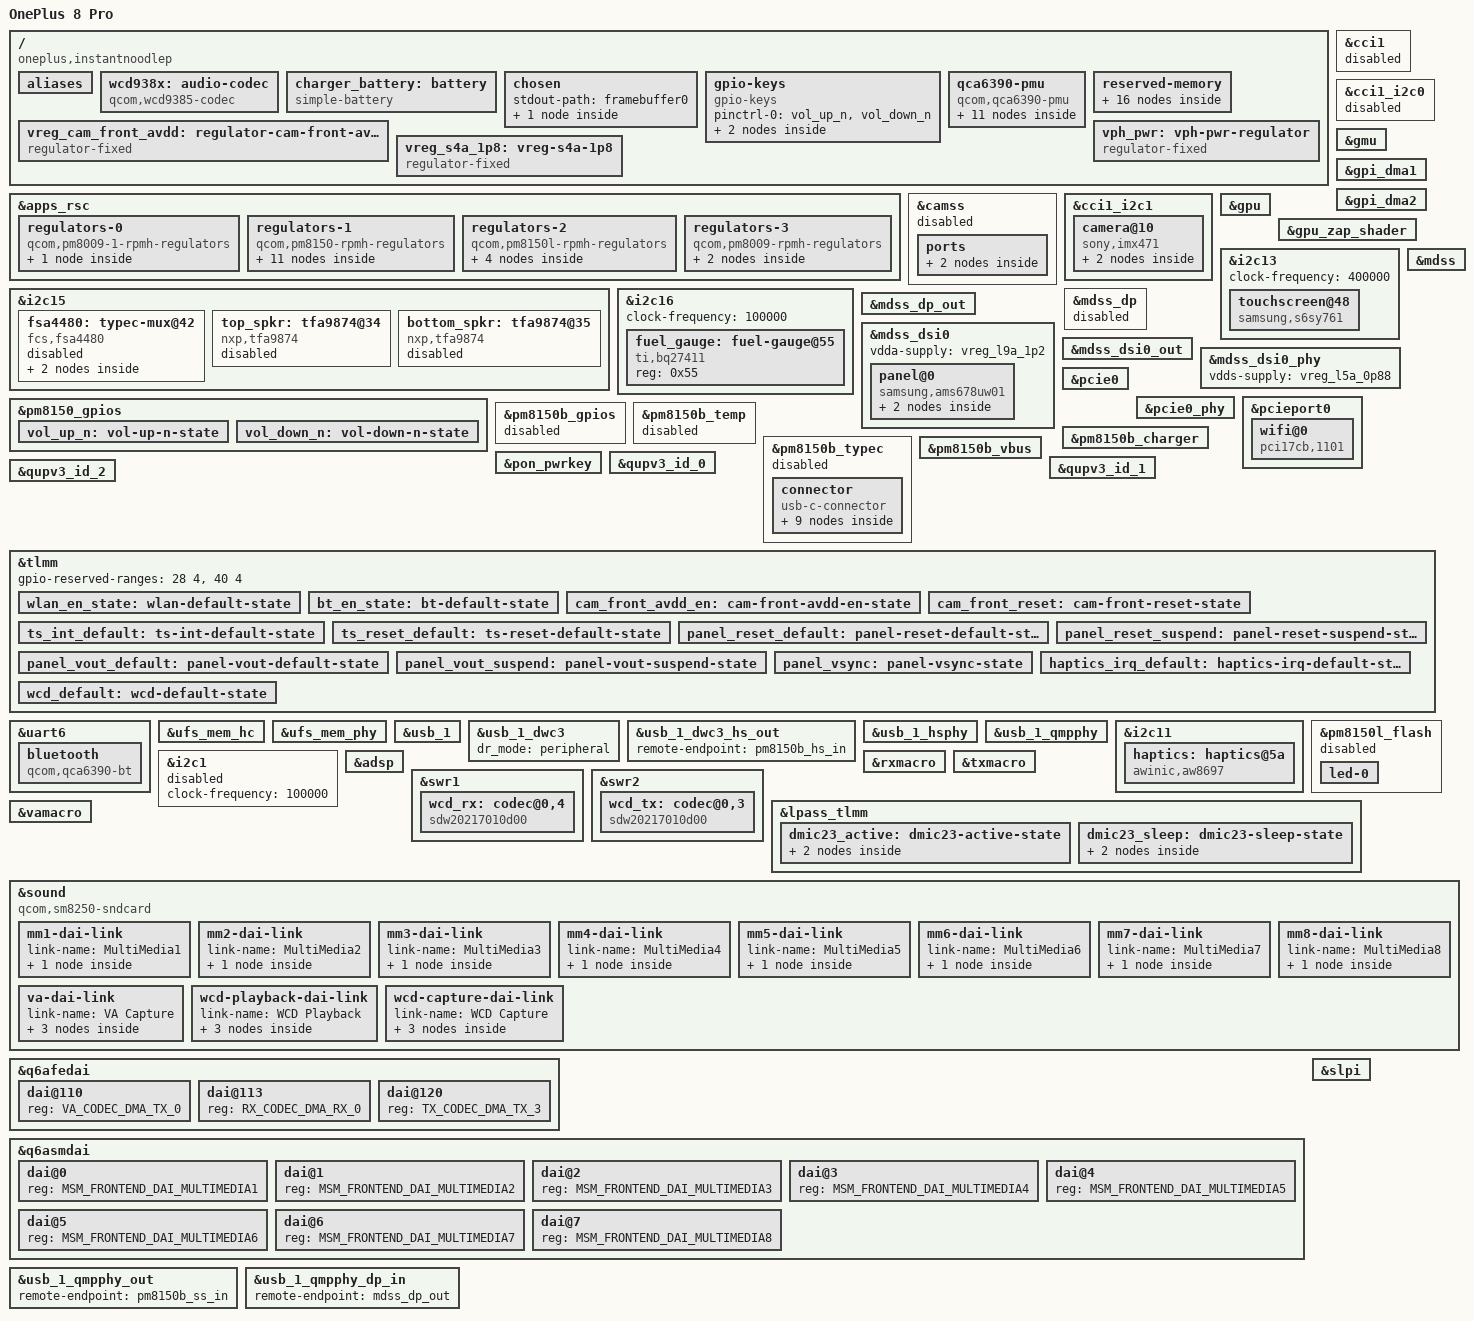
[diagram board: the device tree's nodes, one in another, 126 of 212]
// SPDX-License-Identifier: GPL-2.0
/*
 * Copyright (c) 2023 Pangwalla <pangwalla@protonmail.com>
 *
 * Minimal board support, carried over from the community
 * sm8250-oneplus-instantnoodlep.dts (qualcomm-sm8250 linux, tag 7.2.0-dev).
 */

/dts-v1/;

#include <dt-bindings/gpio/gpio.h>
#include <dt-bindings/input/input.h>
#include <dt-bindings/leds/common.h>
#include <dt-bindings/interrupt-controller/irq.h>
#include <dt-bindings/regulator/qcom,rpmh-regulator.h>
#include <dt-bindings/sound/qcom,q6asm.h>
#include <dt-bindings/sound/qcom,q6dsp-lpass-ports.h>
#include <dt-bindings/usb/pd.h>
#include "sm8250.dtsi"
#include "pm8150.dtsi"
#include "pm8150b.dtsi"
#include "pm8150l.dtsi"
#include "pm8009.dtsi"

/*
 * Delete following upstream (sm8250.dtsi) reserved
 * memory mappings which are different on this device.
 */
/delete-node/ &removed_mem;
/delete-node/ &camera_mem;
/delete-node/ &wlan_mem;
/delete-node/ &ipa_fw_mem;
/delete-node/ &ipa_gsi_mem;
/delete-node/ &gpu_mem;
/delete-node/ &npu_mem;
/delete-node/ &video_mem;
/delete-node/ &cvp_mem;
/delete-node/ &cdsp_mem;
/delete-node/ &slpi_mem;
/delete-node/ &adsp_mem;
/delete-node/ &spss_mem;
/delete-node/ &cdsp_secure_heap;

/ {
	model = "OnePlus 8 Pro";
	compatible = "oneplus,instantnoodlep", "qcom,sm8250";
	chassis-type = "handset";

	qcom,msm-id = <0x164 0x10000>, <0x164 0x20001>;
	qcom,board-id = <0x08 0x00>, <0x00 0x00>;

	aliases {
		serial1 = &uart6;
		i2c1 = &i2c1;
	};

	wcd938x: audio-codec {
		compatible = "qcom,wcd9385-codec";

		pinctrl-0 = <&wcd_default>;
		pinctrl-names = "default";

		qcom,mbhc-buttons-vthreshold-microvolt =
			<75000 150000 237000 500000 500000 500000 500000 500000>;
		qcom,mbhc-headset-vthreshold-microvolt = <2600000>;
		qcom,mbhc-headphone-vthreshold-microvolt = <75000>;
		qcom,micbias1-microvolt = <1800000>;
		qcom,micbias2-microvolt = <2700000>;
		qcom,micbias3-microvolt = <1800000>;
		qcom,micbias4-microvolt = <1800000>;
		qcom,rx-device = <&wcd_rx>;
		qcom,tx-device = <&wcd_tx>;

		reset-gpios = <&tlmm 32 GPIO_ACTIVE_LOW>;

		vdd-buck-supply = <&vreg_s4a_1p8>;
		vdd-rxtx-supply = <&vreg_s4a_1p8>;
		vdd-io-supply = <&vreg_s4a_1p8>;
		vdd-mic-bias-supply = <&vreg_bob>;

		#sound-dai-cells = <1>;
	};

	/*
	 * For the charger only: the fuel gauge must not reference this node,
	 * see &i2c16. 4.35 V is the rated cell voltage, used only without
	 * the fuel-gauge policy; 2 A is the stock normal-temperature limit.
	 */
	charger_battery: battery {
		compatible = "simple-battery";
		voltage-max-design-microvolt = <4350000>;
		constant-charge-current-max-microamp = <2000000>;
	};

	chosen {
		#address-cells = <2>;
		#size-cells = <2>;
		ranges;
		stdout-path = "framebuffer0";

		framebuffer0: framebuffer@9c000000 {
			compatible = "simple-framebuffer";
			reg = <0x0 0x9c000000 0x0 (1080 * 2376 * 4)>;
			width = <1080>;
			height = <2376>;
			stride = <(1080 * 4)>;
			format = "a8r8g8b8";
			clocks = <&dispcc DISP_CC_MDSS_AHB_CLK>,
				 <&gcc GCC_DISP_HF_AXI_CLK>,
				 <&gcc GCC_DISP_SF_AXI_CLK>,
				 <&dispcc DISP_CC_MDSS_VSYNC_CLK>,
				 <&dispcc DISP_CC_MDSS_MDP_CLK>,
				 <&dispcc DISP_CC_MDSS_BYTE0_CLK>,
				 <&dispcc DISP_CC_MDSS_BYTE0_INTF_CLK>,
				 <&dispcc DISP_CC_MDSS_PCLK0_CLK>,
				 <&dispcc DISP_CC_MDSS_ESC0_CLK>;
			power-domains = <&dispcc MDSS_GDSC>;
		};
	};

	gpio-keys {
		compatible = "gpio-keys";

		pinctrl-0 = <&vol_up_n>, <&vol_down_n>;
		pinctrl-names = "default";

		key-vol-up {
			label = "Volume Up";
			gpios = <&pm8150_gpios 6 GPIO_ACTIVE_LOW>;
			linux,code = <KEY_VOLUMEUP>;
			debounce-interval = <15>;
			linux,can-disable;
			wakeup-source;
		};

		key-vol-down {
			label = "Volume Down";
			gpios = <&pm8150_gpios 7 GPIO_ACTIVE_LOW>;
			linux,code = <KEY_VOLUMEDOWN>;
			debounce-interval = <15>;
			linux,can-disable;
			wakeup-source;
		};
	};

	qca6390-pmu {
		compatible = "qcom,qca6390-pmu";

		pinctrl-0 = <&bt_en_state>, <&wlan_en_state>;
		pinctrl-names = "default";

		vddaon-supply = <&vreg_s6a_0p95>;
		vddpmu-supply = <&vreg_s2f_0p95>;
		vddrfa0p95-supply = <&vreg_s2f_0p95>;
		vddrfa1p3-supply = <&vreg_s8c_1p3>;
		vddrfa1p9-supply = <&vreg_s5a_1p9>;
		vddpcie1p3-supply = <&vreg_s8c_1p3>;
		vddpcie1p9-supply = <&vreg_s5a_1p9>;
		vddio-supply = <&vreg_s4a_1p8>;

		wlan-enable-gpios = <&tlmm 20 GPIO_ACTIVE_HIGH>;
		bt-enable-gpios = <&tlmm 21 GPIO_ACTIVE_HIGH>;

		regulators {
			vreg_pmu_rfa_cmn: ldo0 {
				regulator-name = "vreg_pmu_rfa_cmn";
			};

			vreg_pmu_aon_0p59: ldo1 {
				regulator-name = "vreg_pmu_aon_0p59";
			};

			vreg_pmu_wlcx_0p8: ldo2 {
				regulator-name = "vreg_pmu_wlcx_0p8";
			};

			vreg_pmu_wlmx_0p85: ldo3 {
				regulator-name = "vreg_pmu_wlmx_0p85";
			};

			vreg_pmu_btcmx_0p85: ldo4 {
				regulator-name = "vreg_pmu_btcmx_0p85";
			};

			vreg_pmu_rfa_0p8: ldo5 {
				regulator-name = "vreg_pmu_rfa_0p8";
			};

			vreg_pmu_rfa_1p2: ldo6 {
				regulator-name = "vreg_pmu_rfa_1p2";
			};

			vreg_pmu_rfa_1p7: ldo7 {
				regulator-name = "vreg_pmu_rfa_1p7";
			};

			vreg_pmu_pcie_0p9: ldo8 {
				regulator-name = "vreg_pmu_pcie_0p9";
			};

			vreg_pmu_pcie_1p8: ldo9 {
				regulator-name = "vreg_pmu_pcie_1p8";
			};
		};
	};

	vreg_cam_front_avdd: regulator-cam-front-avdd {
		compatible = "regulator-fixed";
		regulator-name = "cam_front_avdd";
		regulator-min-microvolt = <2800000>;
		regulator-max-microvolt = <2800000>;
		startup-delay-us = <2000>;
		gpio = <&tlmm 24 GPIO_ACTIVE_HIGH>;
		enable-active-high;
		vin-supply = <&vreg_bob>;
		pinctrl-0 = <&cam_front_avdd_en>;
		pinctrl-names = "default";
	};

	reserved-memory {
		removed_mem: memory@80b00000 {
			reg = <0x0 0x80b00000 0x0 0xcd00000>;
			no-map;
		};

		camera_mem: memory@8dc00000 {
			reg = <0x0 0x8dc00000 0x0 0x500000>;
			no-map;
		};

		wlan_mem: memory@8e100000 {
			reg = <0x0 0x8e100000 0x0 0x100000>;
			no-map;
		};

		ipa_fw_mem: memory@8e200000 {
			reg = <0x0 0x8e200000 0x0 0x10000>;
			no-map;
		};

		ipa_gsi_mem: memory@8e210000 {
			reg = <0x0 0x8e210000 0x0 0xa000>;
			no-map;
		};

		gpu_mem: memory@8e21a000 {
			reg = <0x0 0x8e21a000 0x0 0x2000>;
			no-map;
		};

		npu_mem: memory@8e300000 {
			reg = <0x0 0x8e300000 0x0 0x500000>;
			no-map;
		};

		video_mem: memory@8e800000 {
			reg = <0x0 0x8e800000 0x0 0x500000>;
			no-map;
		};

		cvp_mem: memory@8ed00000 {
			reg = <0x0 0x8ed00000 0x0 0x500000>;
			no-map;
		};

		cdsp_mem: memory@8f200000 {
			reg = <0x0 0x8f200000 0x0 0x1400000>;
			no-map;
		};

		slpi_mem: memory@90600000 {
			reg = <0x0 0x90600000 0x0 0x1500000>;
			no-map;
		};

		adsp_mem: memory@91b00000 {
			reg = <0x0 0x91b00000 0x0 0x2500000>;
			no-map;
		};

		spss_mem: memory@94000000 {
			reg = <0x0 0x94000000 0x0 0x100000>;
			no-map;
		};

		cdsp_secure_heap: memory@94100000 {
			reg = <0x0 0x94100000 0x0 0x4600000>;
			no-map;
		};

		cont_splash_mem: memory@9c000000 {
			reg = <0x0 0x9c000000 0x0 0x2300000>;
			no-map;
		};

		ramoops@b0000000 {
			compatible = "ramoops";
			reg = <0x0 0xb0000000 0x0 0x400000>;
			record-size = <0x40000>;
			console-size = <0x40000>;
			pmsg-size = <0x40000>;
			ecc-size = <0x0>;
			no-map;
		};
	};

	vph_pwr: vph-pwr-regulator {
		compatible = "regulator-fixed";
		regulator-name = "vph_pwr";
		regulator-min-microvolt = <3700000>;
		regulator-max-microvolt = <3700000>;
	};

	vreg_s4a_1p8: vreg-s4a-1p8 {
		compatible = "regulator-fixed";
		regulator-name = "vreg_s4a_1p8";
		regulator-min-microvolt = <1800000>;
		regulator-max-microvolt = <1800000>;
		regulator-always-on;
	};
};

&apps_rsc {
	regulators-0 {
		compatible = "qcom,pm8009-1-rpmh-regulators";
		qcom,pmic-id = "f";

		vdd-s1-supply = <&vph_pwr>;
		vdd-s2-supply = <&vph_pwr>;

		vreg_s2f_0p95: smps2 {
			regulator-name = "vreg_s2f_0p95";
			regulator-min-microvolt = <900000>;
			regulator-max-microvolt = <952000>;
			regulator-initial-mode = <RPMH_REGULATOR_MODE_AUTO>;
		};
	};

	regulators-1 {
		compatible = "qcom,pm8150-rpmh-regulators";
		qcom,pmic-id = "a";

		vdd-s1-supply = <&vph_pwr>;
		vdd-s2-supply = <&vph_pwr>;
		vdd-s3-supply = <&vph_pwr>;
		vdd-s4-supply = <&vph_pwr>;
		vdd-s5-supply = <&vph_pwr>;
		vdd-s6-supply = <&vph_pwr>;
		vdd-s7-supply = <&vph_pwr>;
		vdd-s8-supply = <&vph_pwr>;
		vdd-s9-supply = <&vph_pwr>;
		vdd-s10-supply = <&vph_pwr>;
		vdd-l2-l10-supply = <&vreg_bob>;
		vdd-l3-l4-l5-l18-supply = <&vreg_s6a_0p95>;
		vdd-l6-l9-supply = <&vreg_s8c_1p3>;
		vdd-l7-l12-l14-l15-supply = <&vreg_s5a_1p9>;
		vdd-l13-l16-l17-supply = <&vreg_bob>;

		vreg_l2a_3p1: ldo2 {
			regulator-name = "vreg_l2a_3p1";
			regulator-min-microvolt = <3072000>;
			regulator-max-microvolt = <3072000>;
			regulator-initial-mode = <RPMH_REGULATOR_MODE_HPM>;
		};

		vreg_l5a_0p88: ldo5 {
			regulator-name = "vreg_l5a_0p88";
			regulator-min-microvolt = <880000>;
			regulator-max-microvolt = <880000>;
			regulator-initial-mode = <RPMH_REGULATOR_MODE_HPM>;
		};

		vreg_l6a_1p2: ldo6 {
			regulator-name = "vreg_l6a_1p2";
			regulator-min-microvolt = <1200000>;
			regulator-max-microvolt = <1200000>;
			regulator-initial-mode = <RPMH_REGULATOR_MODE_HPM>;
		};

		vreg_l9a_1p2: ldo9 {
			regulator-name = "vreg_l9a_1p2";
			regulator-min-microvolt = <1200000>;
			regulator-max-microvolt = <1200000>;
			regulator-initial-mode = <RPMH_REGULATOR_MODE_HPM>;
		};

		vreg_l12a_1p8: ldo12 {
			regulator-name = "vreg_l12a_1p8";
			regulator-min-microvolt = <1800000>;
			regulator-max-microvolt = <1800000>;
			regulator-initial-mode = <RPMH_REGULATOR_MODE_HPM>;
		};

		vreg_l13a_ts_3p0: ldo13 {
			regulator-name = "vreg_l13a_ts_3p0";
			regulator-min-microvolt = <3008000>;
			regulator-max-microvolt = <3008000>;
			regulator-initial-mode = <RPMH_REGULATOR_MODE_HPM>;
		};

		vreg_l14a_1p8: ldo14 {
			regulator-name = "vreg_l14a_1p8";
			regulator-min-microvolt = <1800000>;
			regulator-max-microvolt = <1880000>;
			regulator-initial-mode = <RPMH_REGULATOR_MODE_HPM>;
		};

		vreg_l17a_3p0: ldo17 {
			regulator-name = "vreg_l17a_3p0";
			regulator-min-microvolt = <2856000>;
			regulator-max-microvolt = <3008000>;
			regulator-initial-mode = <RPMH_REGULATOR_MODE_HPM>;
		};

		vreg_l18a_0p92: ldo18 {
			regulator-name = "vreg_l18a_0p92";
			regulator-min-microvolt = <800000>;
			regulator-max-microvolt = <912000>;
			regulator-initial-mode = <RPMH_REGULATOR_MODE_HPM>;
		};

		vreg_s5a_1p9: smps5 {
			regulator-name = "vreg_s5a_1p9";
			regulator-min-microvolt = <1904000>;
			regulator-max-microvolt = <2000000>;
			regulator-initial-mode = <RPMH_REGULATOR_MODE_HPM>;
		};

		vreg_s6a_0p95: smps6 {
			regulator-name = "vreg_s6a_0p95";
			regulator-min-microvolt = <920000>;
			regulator-max-microvolt = <1128000>;
			regulator-initial-mode = <RPMH_REGULATOR_MODE_HPM>;
		};
	};

	regulators-2 {
		compatible = "qcom,pm8150l-rpmh-regulators";
		qcom,pmic-id = "c";

		vdd-s1-supply = <&vph_pwr>;
		vdd-s2-supply = <&vph_pwr>;
		vdd-s3-supply = <&vph_pwr>;
		vdd-s4-supply = <&vph_pwr>;
		vdd-s5-supply = <&vph_pwr>;
		vdd-s6-supply = <&vph_pwr>;
		vdd-s7-supply = <&vph_pwr>;
		vdd-s8-supply = <&vph_pwr>;
		vdd-l1-l8-supply = <&vreg_s4a_1p8>;
		vdd-l2-l3-supply = <&vreg_s8c_1p3>;
		vdd-l4-l5-l6-supply = <&vreg_bob>;
		vdd-l7-l11-supply = <&vreg_bob>;
		vdd-l9-l10-supply = <&vreg_bob>;
		vdd-bob-supply = <&vph_pwr>;

		vreg_bob: bob {
			regulator-name = "vreg_bob";
			regulator-min-microvolt = <3008000>;
			regulator-max-microvolt = <4000000>;
			regulator-initial-mode = <RPMH_REGULATOR_MODE_AUTO>;
		};

		vreg_l1c_1p8: ldo1 {
			regulator-name = "vreg_l1c_1p8";
			regulator-min-microvolt = <1800000>;
			regulator-max-microvolt = <1800000>;
			regulator-initial-mode = <RPMH_REGULATOR_MODE_HPM>;
		};

		vreg_l11c_3p3: ldo11 {
			regulator-name = "vreg_l11c_3p3";
			regulator-min-microvolt = <3296000>;
			regulator-max-microvolt = <3296000>;
			regulator-initial-mode = <RPMH_REGULATOR_MODE_HPM>;
			regulator-always-on;
		};

		vreg_s8c_1p3: smps8 {
			regulator-name = "vreg_s8c_1p3";
			regulator-min-microvolt = <1352000>;
			regulator-max-microvolt = <1352000>;
			regulator-initial-mode = <RPMH_REGULATOR_MODE_HPM>;
		};
	};
	regulators-3 {
		compatible = "qcom,pm8009-rpmh-regulators";
		qcom,pmic-id = "f";
		vdd-l7-supply = <&vreg_s4a_1p8>;

		vreg_l3f_1p05: ldo3 {
			regulator-name = "vreg_l3f_1p05";
			regulator-min-microvolt = <1056000>;
			regulator-max-microvolt = <1056000>;
			regulator-initial-mode = <RPMH_REGULATOR_MODE_HPM>;
		};

		vreg_l7f_1p8: ldo7 {
			regulator-name = "vreg_l7f_1p8";
			regulator-min-microvolt = <1800000>;
			regulator-max-microvolt = <1800000>;
			regulator-initial-mode = <RPMH_REGULATOR_MODE_HPM>;
		};
	};

};


/* Front camera: the 2026-11-18 RAM boot of slim-cam hung before root; off until fixed. */
&camss {
	vdda-phy-supply = <&vreg_l5a_0p88>;
	vdda-pll-supply = <&vreg_l9a_1p2>;
	status = "disabled";

	ports {
		port@3 {
			csiphy3_ep: endpoint {
				clock-lanes = <7>;
				data-lanes = <0 1 2 3>;
				remote-endpoint = <&cam_front_ep>;
			};
		};
	};
};

&cci1 {
	pinctrl-0 = <&cci1_i2c1_default>;
	pinctrl-1 = <&cci1_i2c1_sleep>;
	status = "disabled";
};

&cci1_i2c0 {
	status = "disabled";
};

&cci1_i2c1 {
	camera@10 {
		compatible = "sony,imx471";
		reg = <0x10>;
		clocks = <&camcc CAM_CC_MCLK3_CLK>;
		assigned-clocks = <&camcc CAM_CC_MCLK3_CLK>;
		assigned-clock-rates = <19200000>;
		reset-gpios = <&tlmm 78 GPIO_ACTIVE_LOW>;
		avdd-supply = <&vreg_cam_front_avdd>;
		dvdd-supply = <&vreg_l3f_1p05>;
		dovdd-supply = <&vreg_l7f_1p8>;
		pinctrl-0 = <&cam_mclk3_default>, <&cam_front_reset>;
		pinctrl-names = "default";
		orientation = <0>;
		rotation = <90>;

		port {
			cam_front_ep: endpoint {
				data-lanes = <1 2 3 4>;
				link-frequencies = /bits/ 64 <200000000>;
				remote-endpoint = <&csiphy3_ep>;
			};
		};
	};
};

&gmu {
	status = "okay";
};

&gpi_dma1 {
	status = "okay";
};

&gpi_dma2 {
	status = "okay";
};

&gpu {
	status = "okay";
};

&gpu_zap_shader {
	firmware-name = "qcom/sm8250/OnePlus/instantnoodlep/a650_zap.mbn";
};

&i2c13 {
	clock-frequency = <400000>;
	status = "okay";

	touchscreen@48 {
		compatible = "samsung,s6sy761";
		reg = <0x48>;

		interrupts-extended = <&tlmm 39 IRQ_TYPE_LEVEL_LOW>;
		reset-gpios = <&tlmm 38 GPIO_ACTIVE_LOW>;

		vdd-supply = <&vreg_l13a_ts_3p0>;
		avdd-supply = <&vreg_l1c_1p8>;

		touchscreen-size-x = <1440>;
		touchscreen-size-y = <3168>;

		pinctrl-0 = <&ts_int_default>, <&ts_reset_default>;
		pinctrl-names = "default";
	};
};

&i2c15 {
	status = "okay";

	fsa4480: typec-mux@42 {
		compatible = "fcs,fsa4480";
		reg = <0x42>;
		status = "disabled";

		mode-switch;
		orientation-switch;

		port {
			fsa4480_sbu: endpoint {
				remote-endpoint = <&pm8150b_sbu>;
			};
		};
	};
};

&i2c16 {
	clock-frequency = <100000>;
	status = "okay";

	/*
	 * No monitored-battery: the bq27411 keeps its data memory in RAM,
	 * so the driver would rewrite the gauge's design capacity from a
	 * simple-battery node on every probe. The gauge stays as the stock
	 * firmware left it.
	 */
	fuel_gauge: fuel-gauge@55 {
		compatible = "ti,bq27411";
		reg = <0x55>;
	};
};

&mdss {
	status = "okay";
};

&mdss_dp {
	status = "disabled";
};

&mdss_dp_out {
	data-lanes = <0 1 2 3>;
	link-frequencies = /bits/ 64 <1620000000 2700000000 5400000000 8100000000>;
	remote-endpoint = <&usb_1_qmpphy_dp_in>;
};

&mdss_dsi0 {
	vdda-supply = <&vreg_l9a_1p2>;

	status = "okay";

	panel@0 {
		compatible = "samsung,ams678uw01";
		reg = <0>;

		reset-gpios = <&tlmm 75 GPIO_ACTIVE_LOW>;
		vddio-supply = <&vreg_l14a_1p8>;
		vdd-supply = <&vreg_l11c_3p3>;

		pinctrl-0 = <&panel_reset_default &panel_vout_default &panel_vsync>;
		pinctrl-1 = <&panel_reset_suspend &panel_vout_suspend &panel_vsync>;
		pinctrl-names = "default", "sleep";

		port {
			panel_in: endpoint {
				remote-endpoint = <&mdss_dsi0_out>;
			};
		};
	};
};

&mdss_dsi0_out {
	data-lanes = <0 1 2 3>;
	remote-endpoint = <&panel_in>;
};

&mdss_dsi0_phy {
	vdds-supply = <&vreg_l5a_0p88>;

	status = "okay";
};

&pcie0 {
	status = "okay";
};

&pcie0_phy {
	vdda-phy-supply = <&vreg_l5a_0p88>;
	vdda-pll-supply = <&vreg_l9a_1p2>;

	status = "okay";
};

&pcieport0 {
	wifi@0 {
		compatible = "pci17cb,1101";
		reg = <0x10000 0x0 0x0 0x0 0x0>;

		vddrfacmn-supply = <&vreg_pmu_rfa_cmn>;
		vddaon-supply = <&vreg_pmu_aon_0p59>;
		vddwlcx-supply = <&vreg_pmu_wlcx_0p8>;
		vddwlmx-supply = <&vreg_pmu_wlmx_0p85>;
		vddrfa0p8-supply = <&vreg_pmu_rfa_0p8>;
		vddrfa1p2-supply = <&vreg_pmu_rfa_1p2>;
		vddrfa1p7-supply = <&vreg_pmu_rfa_1p7>;
		vddpcie0p9-supply = <&vreg_pmu_pcie_0p9>;
		vddpcie1p8-supply = <&vreg_pmu_pcie_1p8>;
	};
};

&pm8150_gpios {
	vol_up_n: vol-up-n-state {
		pins = "gpio6";
		function = "normal";
		power-source = <1>;
		input-enable;
		bias-pull-up;
	};

	vol_down_n: vol-down-n-state {
		pins = "gpio7";
		function = "normal";
		power-source = <1>;
		input-enable;
		bias-pull-up;
	};
};

/* Test-only: nothing uses these; keep them out of the charger test. */
&pm8150b_gpios {
	status = "disabled";
};

&pm8150b_temp {
	status = "disabled";
};

&pm8150b_charger {
	monitored-battery = <&charger_battery>;
	/* The gauge at the cell decides when the battery is full, as in stock. */
	qcom,fuel-gauge = <&fuel_gauge>;
	status = "okay";
};

&pm8150b_typec {
	status = "disabled";

	vdd-pdphy-supply = <&vreg_l2a_3p1>;
	vdd-vbus-supply = <&pm8150b_vbus>;

	connector {
		compatible = "usb-c-connector";

		power-role = "dual";
		data-role = "dual";
		self-powered;

		/*
		 * 5 V only until the charger is qualified: stock also offers
		 * 9 V/3 A and 12 V/2.25 A (stock dtbo entry 16), but no driver
		 * programs the PM8150B charger on this kernel.
		 */
		sink-pdos = <PDO_FIXED(5000, 3000, PDO_FIXED_USB_COMM)>;
		op-sink-microwatt = <10000000>;
		source-pdos = <PDO_FIXED(5000, 3000,
					 PDO_FIXED_DUAL_ROLE |
					 PDO_FIXED_USB_COMM |
					 PDO_FIXED_DATA_SWAP)>;

		altmodes {
			displayport {
				svid = /bits/ 16 <0xff01>;
				vdo = <0x00001c46>;
			};
		};

		ports {
			#address-cells = <1>;
			#size-cells = <0>;

			port@0 {
				reg = <0>;
				pm8150b_hs_in: endpoint {
					remote-endpoint = <&usb_1_dwc3_hs_out>;
				};
			};

			port@1 {
				reg = <1>;
				pm8150b_ss_in: endpoint {
					remote-endpoint = <&usb_1_qmpphy_out>;
				};
			};

			port@2 {
				reg = <2>;
				pm8150b_sbu: endpoint {
					remote-endpoint = <&fsa4480_sbu>;
				};
			};
		};
	};
};

&pm8150b_vbus {
	regulator-min-microamp = <500000>;
	regulator-max-microamp = <3000000>;
	status = "okay";
};

&pon_pwrkey {
	status = "okay";
};

&qupv3_id_0 {
	status = "okay";
};

&qupv3_id_1 {
	status = "okay";
};

&qupv3_id_2 {
	status = "okay";
};

&tlmm {
	gpio-reserved-ranges = <28 4>, <40 4>;

	wlan_en_state: wlan-default-state {
		pins = "gpio20";
		function = "gpio";
		drive-strength = <16>;
		output-low;
		bias-pull-up;
	};

	bt_en_state: bt-default-state {
		pins = "gpio21";
		function = "gpio";
		drive-strength = <16>;
		output-low;
		bias-pull-up;
	};

	cam_front_avdd_en: cam-front-avdd-en-state {
		pins = "gpio24";
		function = "gpio";
		drive-strength = <2>;
		bias-disable;
	};

	cam_front_reset: cam-front-reset-state {
		pins = "gpio78";
		function = "gpio";
		drive-strength = <2>;
		bias-disable;
	};

	ts_int_default: ts-int-default-state {
		pins = "gpio39";
		function = "gpio";
		drive-strength = <2>;
		bias-pull-up;
	};

	ts_reset_default: ts-reset-default-state {
		pins = "gpio38";
		function = "gpio";
		drive-strength = <2>;
		bias-disable;
	};

	panel_reset_default: panel-reset-default-state {
		pins = "gpio75";
		function = "gpio";
		drive-strength = <8>;
		bias-disable;
	};

	panel_reset_suspend: panel-reset-suspend-state {
		pins = "gpio75";
		function = "gpio";
		drive-strength = <2>;
		bias-pull-down;
	};

	panel_vout_default: panel-vout-default-state {
		pins = "gpio8";
		function = "gpio";
		drive-strength = <8>;
		bias-disable;
		output-high;
	};

	panel_vout_suspend: panel-vout-suspend-state {
		pins = "gpio8";
		function = "gpio";
		drive-strength = <2>;
		bias-pull-down;
		output-low;
	};

	panel_vsync: panel-vsync-state {
		pins = "gpio66";
		function = "mdp_vsync";
		drive-strength = <2>;
		bias-pull-down;
	};
};

&uart6 {
	status = "okay";

	bluetooth {
		compatible = "qcom,qca6390-bt";

		vddrfacmn-supply = <&vreg_pmu_rfa_cmn>;
		vddaon-supply = <&vreg_pmu_aon_0p59>;
		vddbtcmx-supply = <&vreg_pmu_btcmx_0p85>;
		vddrfa0p8-supply = <&vreg_pmu_rfa_0p8>;
		vddrfa1p2-supply = <&vreg_pmu_rfa_1p2>;
		vddrfa1p7-supply = <&vreg_pmu_rfa_1p7>;
	};
};

&ufs_mem_hc {
	vcc-supply = <&vreg_l17a_3p0>;
	vcc-max-microamp = <800000>;
	vccq-supply = <&vreg_l6a_1p2>;
	vccq-max-microamp = <800000>;
	vccq2-supply = <&vreg_s4a_1p8>;
	vccq2-max-microamp = <800000>;
	status = "okay";
};

&ufs_mem_phy {
	vdda-phy-supply = <&vreg_l5a_0p88>;
	vdda-pll-supply = <&vreg_l9a_1p2>;
	status = "okay";
};

&usb_1 {
	/*
	 * TEST ONLY, not for merging: hold clocks that nobody claims, to find
	 * which one USB needs when clk_ignore_unused is dropped. dwc3-qcom
	 * enables every clock listed here.
	 */
	clocks = <&gcc GCC_CFG_NOC_USB3_PRIM_AXI_CLK>,
		 <&gcc GCC_USB30_PRIM_MASTER_CLK>,
		 <&gcc GCC_AGGRE_USB3_PRIM_AXI_CLK>,
		 <&gcc GCC_USB30_PRIM_SLEEP_CLK>,
		 <&gcc GCC_USB30_PRIM_MOCK_UTMI_CLK>,
		 <&gcc GCC_USB3_SEC_CLKREF_EN>,
		 <&gcc GCC_QUPV3_WRAP1_CORE_CLK>,
		 <&gcc GCC_QUPV3_WRAP1_CORE_2X_CLK>;
	clock-names = "cfg_noc",
		      "core",
		      "iface",
		      "sleep",
		      "mock_utmi",
		      "xo",
		      "test_w1core",
		      "test_w1core2x";
	status = "okay";
};

&usb_1_dwc3 {
	/* Keep the tested USB gadget path independent of the Type-C stack. */
	dr_mode = "peripheral";
};

&usb_1_dwc3_hs_out {
	remote-endpoint = <&pm8150b_hs_in>;
};

&usb_1_hsphy {
	vdda-pll-supply = <&vreg_l5a_0p88>;
	vdda18-supply = <&vreg_l12a_1p8>;
	vdda33-supply = <&vreg_l2a_3p1>;
	status = "okay";
};

&usb_1_qmpphy {
	vdda-phy-supply = <&vreg_l9a_1p2>;
	vdda-pll-supply = <&vreg_l18a_0p92>;
	status = "okay";
};

/* Haptics passed the bounded M3a test on 2026-11-18 (RAM boot). */
&i2c11 {
	status = "okay";

	haptics: haptics@5a {
		compatible = "awinic,aw8697";
		reg = <0x5a>;
		interrupts-extended = <&tlmm 118 IRQ_TYPE_EDGE_FALLING>;
		reset-gpios = <&tlmm 72 GPIO_ACTIVE_HIGH>;
		pinctrl-names = "default";
		pinctrl-0 = <&haptics_irq_default>;
		awinic,f0-preset = <1700>;
		awinic,f0-coefficient = <260>;
		awinic,f0-calibration-percent = <7>;
		awinic,drive-level = <54>;
		awinic,f0-detection-play-time = <5>;
		awinic,f0-detection-wait-time = <3>;
		awinic,f0-detection-repeat = <2>;
		awinic,f0-detection-trace = <15>;
		awinic,boost-debug = /bits/ 8 <0x30 0xeb 0xd4>;
		awinic,tset = /bits/ 8 <0x12>;
		awinic,r-spare = /bits/ 8 <0x68>;
		awinic,bemf-upper-threshold = <4104>;
		awinic,bemf-lower-threshold = <1016>;
		status = "okay";
	};
};

&tlmm {
	haptics_irq_default: haptics-irq-default-state {
		pins = "gpio118";
		function = "gpio";
		drive-strength = <2>;
		bias-pull-up;
	};
};

/* No default trigger; never enable alongside the haptics first-test node. */
&pm8150l_flash {
	status = "disabled";

	led-0 {
		function = LED_FUNCTION_FLASH;
		color = <LED_COLOR_ID_WHITE>;
		led-sources = <1 2>;
		led-max-microamp = <20000>;
		flash-max-microamp = <25000>;
		flash-max-timeout-us = <10000>;
	};
};

/* Controller-only identification: never instantiate unverified Hall clients. */
&i2c1 {
	clock-frequency = <100000>;
	status = "disabled";
};

&adsp {
	status = "okay";
	firmware-name = "qcom/sm8250/OnePlus/instantnoodlep/adsp.mbn";
};

&rxmacro {
	status = "okay";
};

&txmacro {
	status = "okay";
};

&swr1 {
	status = "okay";

	wcd_rx: codec@0,4 {
		compatible = "sdw20217010d00";
		reg = <0 4>;
		qcom,rx-port-mapping = <1 2 3 4 5>;
	};
};

&swr2 {
	status = "okay";

	wcd_tx: codec@0,3 {
		compatible = "sdw20217010d00";
		reg = <0 3>;
		qcom,tx-port-mapping = <2 2 3 4>;
	};
};

&tlmm {
	wcd_default: wcd-default-state {
		pins = "gpio32";
		function = "gpio";
		drive-strength = <16>;
		output-low;
	};
};

/* TFA9874 support is staged separately; no speaker path in phase 1. */
&i2c15 {
	top_spkr: tfa9874@34 {
		compatible = "nxp,tfa9874";
		status = "disabled";
		reg = <0x34>;
		reset-gpios = <&tlmm 91 GPIO_ACTIVE_HIGH>;
		vddd-supply = <&vreg_s4a_1p8>;
		sound-channel = <0>;
		sound-name-prefix = "Top Speaker";
		#sound-dai-cells = <0>;
	};

	bottom_spkr: tfa9874@35 {
		compatible = "nxp,tfa9874";
		status = "disabled";
		reg = <0x35>;
		reset-gpios = <&tlmm 99 GPIO_ACTIVE_HIGH>;
		vddd-supply = <&vreg_s4a_1p8>;
		sound-channel = <1>;
		sound-name-prefix = "Bottom Speaker";
		#sound-dai-cells = <0>;
	};
};

&lpass_tlmm {
	dmic23_active: dmic23-active-state {
		clk-pins {
			pins = "gpio8";
			function = "dmic2_clk";
			drive-strength = <8>;
			output-high;
		};

		data-pins {
			pins = "gpio9";
			function = "dmic2_data";
			drive-strength = <8>;
			input-enable;
		};
	};

	dmic23_sleep: dmic23-sleep-state {
		clk-pins {
			pins = "gpio8";
			function = "dmic2_clk";
			drive-strength = <2>;
			bias-disable;
			output-low;
		};

		data-pins {
			pins = "gpio9";
			function = "dmic2_data";
			drive-strength = <2>;
			bias-pull-down;
			input-enable;
		};
	};
};

&vamacro {
	pinctrl-0 = <&dmic01_active>, <&dmic23_active>;
	pinctrl-1 = <&dmic01_sleep>, <&dmic23_sleep>;
	pinctrl-names = "default", "sleep";
	vdd-micb-supply = <&vreg_bob>;
	qcom,dmic-sample-rate = <2400000>;
};

&sound {
	compatible = "qcom,sm8250-sndcard";
	model = "OnePlus 8 Pro";
	audio-routing =
		"AMIC2", "MIC BIAS2",
		"TX DMIC0", "MIC BIAS1",
		"TX DMIC1", "MIC BIAS1",
		"TX DMIC2", "MIC BIAS3",
		"TX DMIC3", "MIC BIAS4",
		"TX DMIC4", "MIC BIAS4",
		"TX DMIC5", "MIC BIAS4",
		"DMIC1", "MIC BIAS1",
		"DMIC2", "MIC BIAS1",
		"DMIC3", "MIC BIAS3",
		"DMIC4", "MIC BIAS3",
		"DMIC5", "MIC BIAS4",
		"DMIC6", "MIC BIAS4",
		"IN1_HPHL", "HPHL_OUT",
		"IN2_HPHR", "HPHR_OUT",
		"IN3_AUX", "AUX_OUT",
		"TX SWR_ADC0", "ADC1_OUTPUT",
		"TX SWR_ADC1", "ADC2_OUTPUT",
		"TX SWR_ADC2", "ADC3_OUTPUT",
		"TX SWR_ADC3", "ADC4_OUTPUT",
		"TX SWR_DMIC0", "DMIC1_OUTPUT",
		"TX SWR_DMIC1", "DMIC2_OUTPUT",
		"TX SWR_DMIC2", "DMIC3_OUTPUT",
		"TX SWR_DMIC3", "DMIC4_OUTPUT",
		"TX SWR_DMIC4", "DMIC5_OUTPUT",
		"TX SWR_DMIC5", "DMIC6_OUTPUT",
		"TX SWR_DMIC6", "DMIC7_OUTPUT",
		"TX SWR_DMIC7", "DMIC8_OUTPUT",
		"RX_TX DEC0_INP", "TX DEC0 MUX",
		"RX_TX DEC1_INP", "TX DEC1 MUX",
		"RX_TX DEC2_INP", "TX DEC2 MUX",
		"RX_TX DEC3_INP", "TX DEC3 MUX",
		"VA DMIC0", "VA MIC BIAS1",
		"VA DMIC1", "VA MIC BIAS1",
		"VA DMIC2", "VA MIC BIAS3",
		"VA DMIC3", "VA MIC BIAS4",
		"VA DMIC4", "VA MIC BIAS4",
		"VA DMIC5", "VA MIC BIAS4",
		"VA SWR_ADC0", "ADC1_OUTPUT",
		"VA SWR_ADC1", "ADC2_OUTPUT",
		"VA SWR_ADC2", "ADC3_OUTPUT",
		"VA SWR_ADC3", "ADC4_OUTPUT",
		"VA SWR_MIC0", "DMIC1_OUTPUT",
		"VA SWR_MIC1", "DMIC2_OUTPUT",
		"VA SWR_MIC2", "DMIC3_OUTPUT",
		"VA SWR_MIC3", "DMIC4_OUTPUT",
		"VA SWR_MIC4", "DMIC5_OUTPUT",
		"VA SWR_MIC5", "DMIC6_OUTPUT",
		"VA SWR_MIC6", "DMIC7_OUTPUT",
		"VA SWR_MIC7", "DMIC8_OUTPUT";
	mm1-dai-link {
		link-name = "MultiMedia1";

		cpu {
			sound-dai = <&q6asmdai MSM_FRONTEND_DAI_MULTIMEDIA1>;
		};
	};

	mm2-dai-link {
		link-name = "MultiMedia2";

		cpu {
			sound-dai = <&q6asmdai MSM_FRONTEND_DAI_MULTIMEDIA2>;
		};
	};

	mm3-dai-link {
		link-name = "MultiMedia3";

		cpu {
			sound-dai = <&q6asmdai MSM_FRONTEND_DAI_MULTIMEDIA3>;
		};
	};

	mm4-dai-link {
		link-name = "MultiMedia4";

		cpu {
			sound-dai = <&q6asmdai MSM_FRONTEND_DAI_MULTIMEDIA4>;
		};
	};

	mm5-dai-link {
		link-name = "MultiMedia5";

		cpu {
			sound-dai = <&q6asmdai MSM_FRONTEND_DAI_MULTIMEDIA5>;
		};
	};

	mm6-dai-link {
		link-name = "MultiMedia6";

		cpu {
			sound-dai = <&q6asmdai MSM_FRONTEND_DAI_MULTIMEDIA6>;
		};
	};

	mm7-dai-link {
		link-name = "MultiMedia7";

		cpu {
			sound-dai = <&q6asmdai MSM_FRONTEND_DAI_MULTIMEDIA7>;
		};
	};

	mm8-dai-link {
		link-name = "MultiMedia8";

		cpu {
			sound-dai = <&q6asmdai MSM_FRONTEND_DAI_MULTIMEDIA8>;
		};
	};

	va-dai-link {
		link-name = "VA Capture";

		codec {
			sound-dai = <&vamacro 0>;
		};

		cpu {
			sound-dai = <&q6afedai VA_CODEC_DMA_TX_0>;
		};

		platform {
			sound-dai = <&q6routing>;
		};
	};

	wcd-playback-dai-link {
		link-name = "WCD Playback";

		codec {
			sound-dai = <&wcd938x 0>, <&swr1 0>, <&rxmacro 0>;
		};

		cpu {
			sound-dai = <&q6afedai RX_CODEC_DMA_RX_0>;
		};

		platform {
			sound-dai = <&q6routing>;
		};
	};

	wcd-capture-dai-link {
		link-name = "WCD Capture";

		codec {
			sound-dai = <&wcd938x 1>, <&swr2 0>, <&txmacro 0>;
		};

		cpu {
			sound-dai = <&q6afedai TX_CODEC_DMA_TX_3>;
		};

		platform {
			sound-dai = <&q6routing>;
		};
	};
};

&q6afedai {

	dai@110 {
		reg = <VA_CODEC_DMA_TX_0>;
	};

	dai@113 {
		reg = <RX_CODEC_DMA_RX_0>;
	};

	dai@120 {
		reg = <TX_CODEC_DMA_TX_3>;
	};

};

&q6asmdai {
	dai@0 {
		reg = <MSM_FRONTEND_DAI_MULTIMEDIA1>;
	};

	dai@1 {
		reg = <MSM_FRONTEND_DAI_MULTIMEDIA2>;
	};

	dai@2 {
		reg = <MSM_FRONTEND_DAI_MULTIMEDIA3>;
	};

	dai@3 {
		reg = <MSM_FRONTEND_DAI_MULTIMEDIA4>;
	};

	dai@4 {
		reg = <MSM_FRONTEND_DAI_MULTIMEDIA5>;
	};

	dai@5 {
		reg = <MSM_FRONTEND_DAI_MULTIMEDIA6>;
	};

	dai@6 {
		reg = <MSM_FRONTEND_DAI_MULTIMEDIA7>;
	};

	dai@7 {
		reg = <MSM_FRONTEND_DAI_MULTIMEDIA8>;
	};
};


&slpi {
	firmware-name = "qcom/sm8250/OnePlus/instantnoodlep/slpi.mbn";
	status = "okay";
};

&usb_1_qmpphy_out {
	remote-endpoint = <&pm8150b_ss_in>;
};

&usb_1_qmpphy_dp_in {
	remote-endpoint = <&mdss_dp_out>;
};
